# nrf5340_network register map
Vendor: Nordic Semiconductor; Series: nrf53; File version: 1
CPU: CM33 r0p4, little endian, MPU, no FPU, 3 interrupt priority bits, 30 interrupts
Registers are 32-bit, read-write, reset 0x0 unless marked. A register's access mark holds for its fields unless they carry their own. Offsets are from the block's base; [hi:lo] are bit positions; {n}, {i} and the like mark numbered series; 'fields as' and 'values as' point back to an identical list.

## TEMP_NS — Temperature Sensor
Base 0x41010000
0x00 TASKS_START wo — Start temperature measurement
  [0] TASKS_START
    1=Trigger task
0x04 TASKS_STOP wo — Stop temperature measurement
  [0] TASKS_STOP
    1=Trigger task
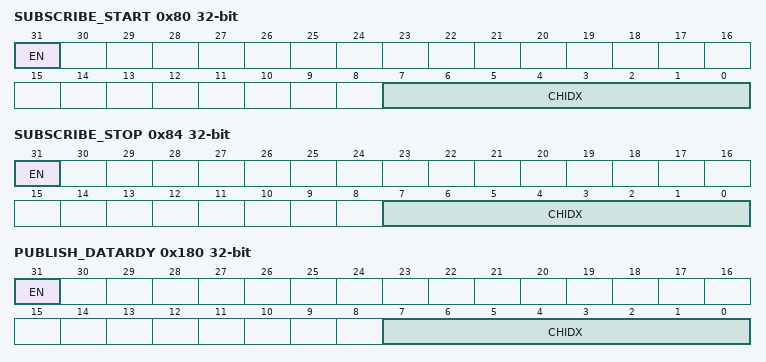
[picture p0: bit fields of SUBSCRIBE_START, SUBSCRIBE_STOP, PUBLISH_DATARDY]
0x80 SUBSCRIBE_START — Subscribe configuration for task START
  [31] EN
    0=Disabled (Disable subscription); 1=Enabled (Enable subscription)
  [7:0] CHIDX — DPPI channel that task START will subscribe to
0x84 SUBSCRIBE_STOP — Subscribe configuration for task STOP
  [31] EN
    values as SUBSCRIBE_START.EN
  [7:0] CHIDX — DPPI channel that task STOP will subscribe to
0x100 EVENTS_DATARDY — Temperature measurement complete, data ready
  [0] EVENTS_DATARDY
    0=NotGenerated (Event not generated); 1=Generated (Event generated)
0x180 PUBLISH_DATARDY — Publish configuration for event DATARDY
  [31] EN
    0=Disabled (Disable publishing); 1=Enabled (Enable publishing)
  [7:0] CHIDX — DPPI channel that event DATARDY will publish to.
0x304 INTENSET — Enable interrupt
  [0] DATARDY — Write '1' to enable interrupt for event DATARDY
    on read: 0=Disabled (Read: Disabled); 1=Enabled (Read: Enabled) | on write: 1=Set (Enable)
0x308 INTENCLR — Disable interrupt
  [0] DATARDY — Write '1' to disable interrupt for event DATARDY
    on read: 0=Disabled (Read: Disabled); 1=Enabled (Read: Enabled) | on write: 1=Clear (Disable)
0x508 TEMP ro — Temperature in degC (0.25deg steps)
0x520 A0 reset 0x2D9 — Slope of first piecewise linear function
  [11:0] A0
0x524 A1 reset 0x322 — Slope of second piecewise linear function
  [11:0] A1
0x528 A2 reset 0x355 — Slope of third piecewise linear function
  [11:0] A2
0x52C A3 reset 0x3DF — Slope of fourth piecewise linear function
  [11:0] A3
0x530 A4 reset 0x44E — Slope of fifth piecewise linear function
  [11:0] A4
0x534 A5 reset 0x4B7 — Slope of sixth piecewise linear function
  [11:0] A5
0x540 B0 reset 0xFC7 — y-intercept of first piecewise linear function
  [11:0] B0
0x544 B1 reset 0xF71 — y-intercept of second piecewise linear function
  [11:0] B1
0x548 B2 reset 0xF6C — y-intercept of third piecewise linear function
  [11:0] B2
0x54C B3 reset 0xFCB — y-intercept of fourth piecewise linear function
  [11:0] B3
0x550 B4 reset 0x4B — y-intercept of fifth piecewise linear function
  [11:0] B4
0x554 B5 reset 0xF6 — y-intercept of sixth piecewise linear function
  [11:0] B5
0x560 T0 reset 0xE1 — Endpoint of first piecewise linear function
  [7:0] T0
0x564 T1 reset 0xF9 — Endpoint of second piecewise linear function
  [7:0] T1
0x568 T2 reset 0x10 — Endpoint of third piecewise linear function
  [7:0] T2
0x56C T3 reset 0x26 — Endpoint of fourth piecewise linear function
  [7:0] T3
0x570 T4 reset 0x3F — Endpoint of fifth piecewise linear function
  [7:0] T4

## IPC_NS — Interprocessor communication
Base 0x41012000
{0x0+4i} TASKS_SEND[{i}] (i=0..15) wo — Description collection: Trigger events on IPC channel enabled in SEND_CNF[n]
  [0] TASKS_SEND — Trigger events on IPC channel enabled in SEND_CNF[n]
    1=Trigger task
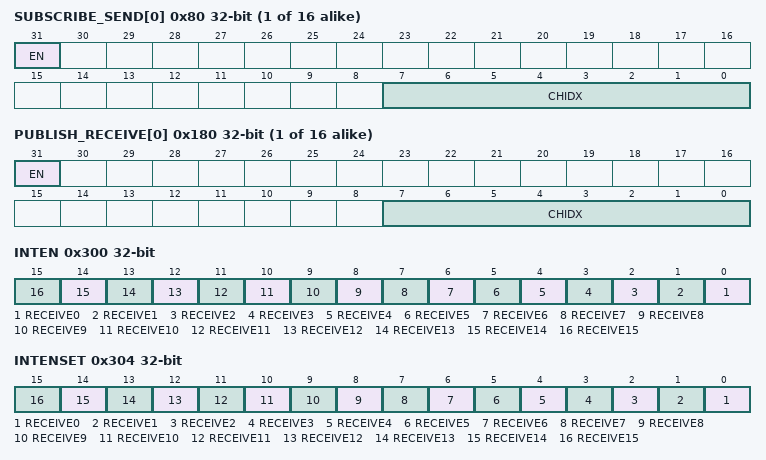
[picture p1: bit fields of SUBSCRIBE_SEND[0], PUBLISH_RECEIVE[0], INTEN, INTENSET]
{0x80+4i} SUBSCRIBE_SEND[{i}] (i=0..15) — Description collection: Subscribe configuration for task SEND[n]
  [31] EN
    0=Disabled (Disable subscription); 1=Enabled (Enable subscription)
  [7:0] CHIDX — DPPI channel that task SEND[n] will subscribe to
{0x100+4i} EVENTS_RECEIVE[{i}] (i=0..15) — Description collection: Event received on one or more of the enabled IPC channels in RECEIVE_CNF[n]
  [0] EVENTS_RECEIVE — Event received on one or more of the enabled IPC channels in RECEIVE_CNF[n]
    0=NotGenerated (Event not generated); 1=Generated (Event generated)
{0x180+4i} PUBLISH_RECEIVE[{i}] (i=0..15) — Description collection: Publish configuration for event RECEIVE[n]
  [31] EN
    0=Disabled (Disable publishing); 1=Enabled (Enable publishing)
  [7:0] CHIDX — DPPI channel that event RECEIVE[n] will publish to.
0x300 INTEN — Enable or disable interrupt
  [all] fields
    0=Disabled; 1=Enabled
  [n] RECEIVE{n} (n=0..15) — Enable or disable interrupt for event RECEIVE[{n}]
0x304 INTENSET — Enable interrupt
  [all] fields
    on read: 0=Disabled (Read: Disabled); 1=Enabled (Read: Enabled) | on write: 1=Set (Enable)
  [n] RECEIVE{n} (n=0..15) — Write '1' to enable interrupt for event RECEIVE[{n}]
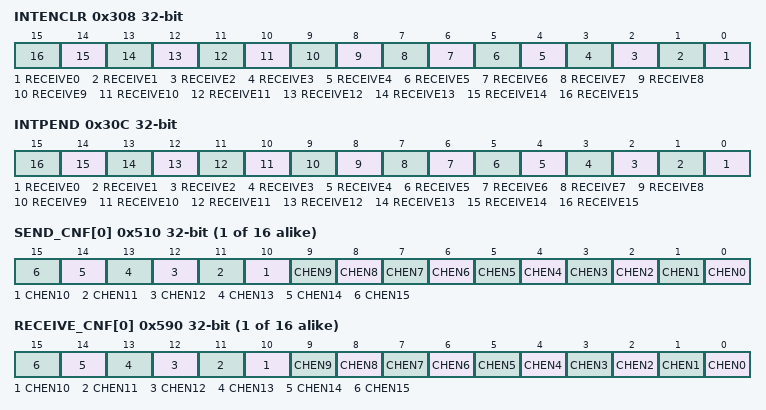
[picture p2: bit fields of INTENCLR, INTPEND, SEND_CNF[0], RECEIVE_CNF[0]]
0x308 INTENCLR — Disable interrupt
  [all] fields
    on read: 0=Disabled (Read: Disabled); 1=Enabled (Read: Enabled) | on write: 1=Clear (Disable)
  [n] RECEIVE{n} (n=0..15) — Write '1' to disable interrupt for event RECEIVE[{n}]
0x30C INTPEND ro — Pending interrupts
  [all] fields
    on read: 0=NotPending (Read: Not pending); 1=Pending (Read: Pending)
  [n] RECEIVE{n} (n=0..15) — Read pending status of interrupt for event RECEIVE[{n}]
{0x510+4i} SEND_CNF[{i}] (i=0..15) — Description collection: Send event configuration for TASKS_SEND[n]
  [all] fields
    0=Disable broadcast; 1=Enable broadcast
  [n] CHEN{n} (n=0..15) — Enable broadcasting on IPC channel {n}
{0x590+4i} RECEIVE_CNF[{i}] (i=0..15) — Description collection: Receive event configuration for EVENTS_RECEIVE[n]
  [all] fields
    0=Disable events; 1=Enable events
  [n] CHEN{n} (n=0..15) — Enable subscription to IPC channel {n}
{0x610+4i} GPMEM[{i}] (i=0..1) — Description collection: General purpose memory
  [31:0] GPMEM — General purpose memory
